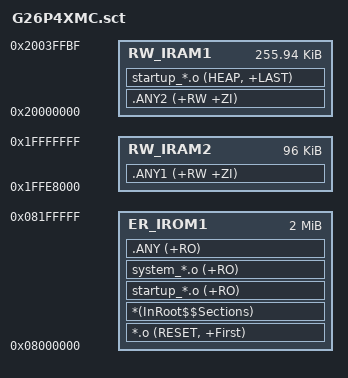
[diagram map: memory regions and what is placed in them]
; *************************************************************
; *** Scatter-Loading Description File generated by uVision ***
; *************************************************************

LR_IROM1 0x08000000 0x00200000  {    ; load region size_region
  ER_IROM1 0x08000000 0x00200000  {  ; load address = execution address
   *.o (RESET, +First)
   *(InRoot$$Sections)
   startup_*.o (+RO)
   system_*.o (+RO)
   .ANY (+RO)
  }

  RW_IRAM1 0x20000000 0x3FFC0  {  ; RW data
   .ANY2 (+RW +ZI)
   startup_*.o (HEAP, +LAST)
  }

  RW_IRAM2 0x1FFE8000 0x18000  {  ; RO data
   .ANY1 (+RW +ZI)
  }

}

